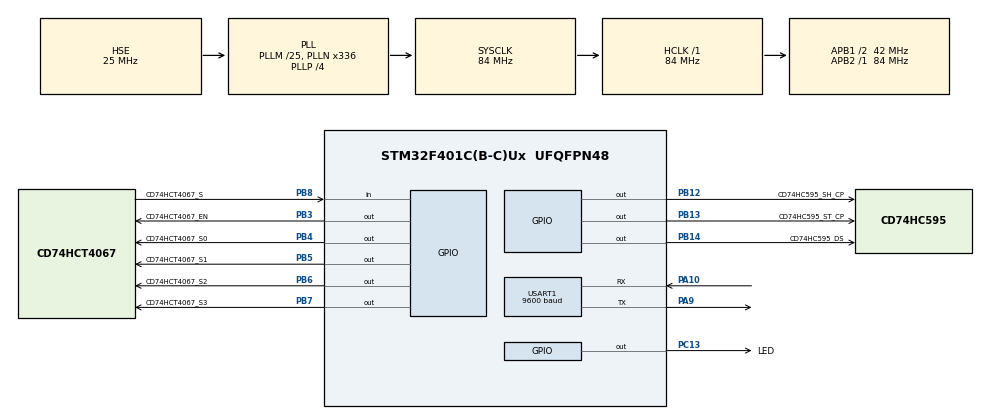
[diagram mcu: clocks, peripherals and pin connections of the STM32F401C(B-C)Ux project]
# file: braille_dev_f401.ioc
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FREERTOS.INCLUDE_vTaskDelayUntil=1
FREERTOS.Tasks01=defaultTask,0,128,StartDefaultTask,Default,NULL,Dynamic,NULL,NULL
FREERTOS.configUSE_NEWLIB_REENTRANT=1
FREERTOS.configUSE_TIMERS=1
Mcu.Family=STM32F4
Mcu.Name=STM32F401C(B-C)Ux
Mcu.Package=UFQFPN48
NVIC.PriorityGroup=NVIC_PRIORITYGROUP_4
NVIC.TIM1_TRG_COM_TIM11_IRQn=true\:15\:0\:false\:false\:true\:false\:false\:true\:true
NVIC.TimeBase=TIM1_TRG_COM_TIM11_IRQn
NVIC.TimeBaseIP=TIM11
NVIC.USART1_IRQn=true\:5\:0\:false\:false\:true\:true\:true\:true\:true
PA10.Mode=Asynchronous
PA10.Signal=USART1_RX
PA9.Mode=Asynchronous
PA9.Signal=USART1_TX
PB12.GPIO_Label=CD74HC595_SH_CP
PB12.Signal=GPIO_Output
PB13.GPIO_Label=CD74HC595_ST_CP
PB13.Signal=GPIO_Output
PB14.GPIO_Label=CD74HC595_DS
PB14.Signal=GPIO_Output
PB3.GPIO_Label=CD74HCT4067_EN
PB3.Signal=GPIO_Output
PB4.GPIO_Label=CD74HCT4067_S0
PB4.Signal=GPIO_Output
PB5.GPIO_Label=CD74HCT4067_S1
PB5.Signal=GPIO_Output
PB6.GPIO_Label=CD74HCT4067_S2
PB6.Signal=GPIO_Output
PB7.GPIO_Label=CD74HCT4067_S3
PB7.Signal=GPIO_Output
PB8.GPIO_Label=CD74HCT4067_S
PB8.Signal=GPIO_Input
PC13-ANTI_TAMP.GPIO_Label=LED
PC13-ANTI_TAMP.Signal=GPIO_Output
PC14-OSC32_IN.Mode=LSE-External-Oscillator
PC14-OSC32_IN.Signal=RCC_OSC32_IN
PC15-OSC32_OUT.Mode=LSE-External-Oscillator
PC15-OSC32_OUT.Signal=RCC_OSC32_OUT
PH0\ -\ OSC_IN.Mode=HSE-External-Oscillator
PH0\ -\ OSC_IN.Signal=RCC_OSC_IN
PH1\ -\ OSC_OUT.Mode=HSE-External-Oscillator
PH1\ -\ OSC_OUT.Signal=RCC_OSC_OUT
ProjectManager.HeapSize=0x200
ProjectManager.StackSize=0x400
ProjectManager.TargetToolchain=STM32CubeIDE
RCC.48MHZClocksFreq_Value=48000000
RCC.AHBFreq_Value=84000000
RCC.APB1CLKDivider=RCC_HCLK_DIV2
RCC.APB1Freq_Value=42000000
RCC.APB1TimFreq_Value=84000000
RCC.APB2Freq_Value=84000000
RCC.APB2TimFreq_Value=84000000
RCC.CortexFreq_Value=84000000
RCC.HCLKFreq_Value=84000000
RCC.HSE_VALUE=25000000
RCC.HSI_VALUE=16000000
RCC.PLLM=25
RCC.PLLN=336
RCC.PLLP=RCC_PLLP_DIV4
RCC.PLLQ=7
RCC.PLLSourceVirtual=RCC_PLLSOURCE_HSE
RCC.SYSCLKFreq_VALUE=84000000
RCC.SYSCLKSource=RCC_SYSCLKSOURCE_PLLCLK
RCC.VCOOutputFreq_Value=336000000
USART1.BaudRate=9600
USART1.VirtualMode=VM_ASYNC
VP_FREERTOS_VS_CMSIS_V1.Mode=CMSIS_V1
VP_SYS_VS_tim11.Mode=TIM11
board=custom

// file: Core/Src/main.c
/* USER CODE BEGIN Header */
/**
  ******************************************************************************
  * @file           : main.c
  * @brief          : Main program body
  ******************************************************************************
  * @attention
  *
  * Copyright (c) 2024 STMicroelectronics.
  * All rights reserved.
  *
  * This software is licensed under terms that can be found in the LICENSE file
  * in the root directory of this software component.
  * If no LICENSE file comes with this software, it is provided AS-IS.
  *
  ******************************************************************************
  */
/* USER CODE END Header */
#include "main.h"
#include "cmsis_os.h"
#include "usart.h"
#include "gpio.h"

/* USER CODE BEGIN Includes */
#include "braille_driver.h"
/* USER CODE END Includes */

/* USER CODE BEGIN PTD */
uint32_t counter = 0;
uint8_t rx_data[32];
uint8_t tx_data[8];
uint8_t rx_flag;
/* USER CODE END PTD */

void SystemClock_Config(void);
void MX_FREERTOS_Init(void);

int main(void)
{

  /* MCU Configuration--------------------------------------------------------*/

  /* Reset of all peripherals, Initializes the Flash interface and the Systick. */
  HAL_Init();

  /* Configure the system clock */
  SystemClock_Config();

  /* Initialize all configured peripherals */
  MX_GPIO_Init();
  MX_USART1_UART_Init();
  /* USER CODE BEGIN 2 */

  braille_dev_init();
  /* USER CODE END 2 */

  /* Call init function for freertos objects (in freertos.c) */
  MX_FREERTOS_Init();

  /* Start scheduler */
  osKernelStart();

  /* We should never get here as control is now taken by the scheduler */
  /* Infinite loop */
  while (1)
  {

  }
}

void SystemClock_Config(void)
{
  RCC_OscInitTypeDef RCC_OscInitStruct = {0};
  RCC_ClkInitTypeDef RCC_ClkInitStruct = {0};

  /** Configure the main internal regulator output voltage
  */
  __HAL_RCC_PWR_CLK_ENABLE();
  __HAL_PWR_VOLTAGESCALING_CONFIG(PWR_REGULATOR_VOLTAGE_SCALE2);

  /** Initializes the RCC Oscillators according to the specified parameters
  * in the RCC_OscInitTypeDef structure.
  */
  RCC_OscInitStruct.OscillatorType = RCC_OSCILLATORTYPE_HSE;
  RCC_OscInitStruct.HSEState = RCC_HSE_ON;
  RCC_OscInitStruct.PLL.PLLState = RCC_PLL_ON;
  RCC_OscInitStruct.PLL.PLLSource = RCC_PLLSOURCE_HSE;
  RCC_OscInitStruct.PLL.PLLM = 25;
  RCC_OscInitStruct.PLL.PLLN = 336;
  RCC_OscInitStruct.PLL.PLLP = RCC_PLLP_DIV4;
  RCC_OscInitStruct.PLL.PLLQ = 7;
  if (HAL_RCC_OscConfig(&RCC_OscInitStruct) != HAL_OK)
  {
    Error_Handler();
  }

  /** Initializes the CPU, AHB and APB buses clocks
  */
  RCC_ClkInitStruct.ClockType = RCC_CLOCKTYPE_HCLK|RCC_CLOCKTYPE_SYSCLK
                              |RCC_CLOCKTYPE_PCLK1|RCC_CLOCKTYPE_PCLK2;
  RCC_ClkInitStruct.SYSCLKSource = RCC_SYSCLKSOURCE_PLLCLK;
  RCC_ClkInitStruct.AHBCLKDivider = RCC_SYSCLK_DIV1;
  RCC_ClkInitStruct.APB1CLKDivider = RCC_HCLK_DIV2;
  RCC_ClkInitStruct.APB2CLKDivider = RCC_HCLK_DIV1;

  if (HAL_RCC_ClockConfig(&RCC_ClkInitStruct, FLASH_LATENCY_2) != HAL_OK)
  {
    Error_Handler();
  }
}

void HAL_TIM_PeriodElapsedCallback(TIM_HandleTypeDef *htim)
{
  if (htim->Instance == TIM11) {
    HAL_IncTick();
  }
}

void Error_Handler(void)
{
  __disable_irq();
  while (1)
  {
  }
}
